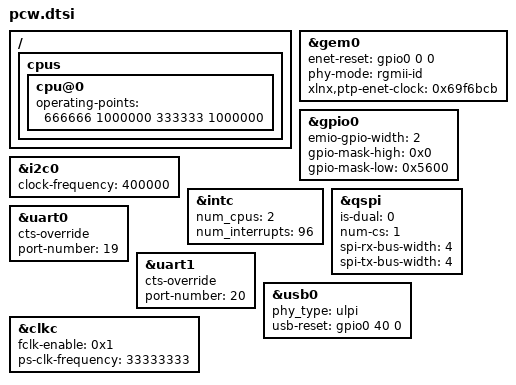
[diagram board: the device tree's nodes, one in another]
/*
 * CAUTION: This file is automatically generated by Xilinx.
 * Version:  
 * Today is: Thu Jul 18 16:22:56 2024
 */


/ {
	cpus {
		cpu@0 {
			operating-points = <666666 1000000 333333 1000000>;
		};
	};
};
&gem0 {
	enet-reset = <&gpio0 0 0>;
	phy-mode = "rgmii-id";
	status = "okay";
	xlnx,ptp-enet-clock = <0x69f6bcb>;
};
&gpio0 {
	emio-gpio-width = <2>;
	gpio-mask-high = <0x0>;
	gpio-mask-low = <0x5600>;
};
&i2c0 {
	clock-frequency = <400000>;
	status = "okay";
};
&intc {
	num_cpus = <2>;
	num_interrupts = <96>;
};
&qspi {
	is-dual = <0>;
	num-cs = <1>;
	spi-rx-bus-width = <4>;
	spi-tx-bus-width = <4>;
	status = "okay";
};
&uart0 {
	cts-override ;
	device_type = "serial";
	port-number = <19>;
	status = "okay";
};
&uart1 {
	cts-override ;
	device_type = "serial";
	port-number = <20>;
	status = "okay";
};
&usb0 {
	phy_type = "ulpi";
	status = "okay";
	usb-reset = <&gpio0 40 0>;
};
&clkc {
	fclk-enable = <0x1>;
	ps-clk-frequency = <33333333>;
};
